# TN2115s1 register map
Vendor: Fusens Micro Ltd.; Series: TN21xx; File version: 1.0
ARM 32-bit Cortex-M0 Microcontroller Embedded in TN2115s1 device.
CPU: CM0 r0p0, little endian, no MPU, no FPU, 2 interrupt priority bits
Registers are 8-bit, read-write, reset 0x0 unless marked. A register's access mark holds for its fields unless they carry their own. Offsets are from the block's base; lines under a group give offsets from that group; [hi:lo] are bit positions; {n}, {i} and the like mark numbered series; 'fields as' and 'values as' point back to an identical list; <NAME> marks a mode.

## Memory map
0x40000000 I2C size 0x1C — I2C interface
0x40000100 SPI size 0x20 — SPI interface
0x40000200 UART size 0x18 — UART interface
0x40000300 NFC size 0x29 — NFC System Control
0x40000400 WDT size 0x10 — Watchdog Timer
0x40000404 TIM32 size 0x10 — General Purpose 32bit Timer
0x40000500 GPIO size 0xD
0x40000600 FLASH size 0x8

## Interrupts
0 UART
1 SPI
2 I2C
3 NFCTX (NFC)
4 NFCRX (NFC)
5 NFCFIELD (NFC)
6 TIM32
8 CAP_OK (NFC)

## WDT — Watchdog Timer
Base 0x40000400
0x00 CSR 32-bit reset 0x4 — Watchdog Control and Status Register

## I2C — I2C interface
Base 0x40000000
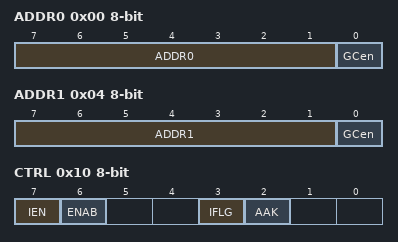
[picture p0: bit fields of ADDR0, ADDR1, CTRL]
0x00 ADDR0 — I2C Slave Address 0 Register
  [7:1] ADDR0 — Address 0
  [0] GCen — General call enable
    1=ON (General call enabled); 0=OFF (General call disabled)
0x04 ADDR1 — I2C Slave Address 1 Register
  [7:1] ADDR1 — Address 0
  [0] GCen — General call enable
    1=ON (General call enabled); 0=OFF (General call disabled)
0x0C DATA — I2C RTX Data Register
  [7:0] DATA — Data to receive or transmit
0x10 CTRL — I2C CTRL Register
  [7] IEN — Interrupt enable
    1=ON (Enabled); 0=OFF (Disabled)
  [6] ENAB — I2C Enable
    1=ON (Enabled); 0=OFF (Disabled)
  [3] IFLG — Interrupt flag
    1=SET (Interrupt set); 0=CLR (Interrupt clear)
  [2] AAK — Acknowlegement control
    1=ACK (Enable ACK); 0=NACK (Enable NACK)
0x18 STATUS — I2C Status Register
  [7:0] STAT ro — Status display
    0=ERR (Bus Error); 8=M_ST_TX (Start Txed); 16=M_ReST_TX (Restart Txed); 24=M_ADRWTX_ACK (Address+W TXed and ACKed); 32=M_ADRWTX (Address+W TXed); 40=M_TX_ACK (Data Txed and ACKed); 48=M_TX (Data Txed); 64=M_ADRRTX_ACK (Address+R TXed and ACKed); 72=M_ADRRTX (Address+R TXed); 80=M_RX_ACK (Data RXed and ACKed); 88=M_RX_NACK (Data RXed and NACKed); 96=S_ADRW_ACK (Address+W RXed and ACKed); 112=S_GC_ACK (General call RXed and ACKed); 128=S_RX_ACK (Data RXed and ACKed); 136=S_RX_NACK (Data RXed and NACKed); 160=S_ReST (Stop or Restart RXed); 168=S_ADRR_ACK (Address+R RXed and ACKed); 184=S_TX_ACK (Data TXed and ACKed); 192=S_TX (Data TXed); 200=S_TX_NACK (Data TXed and NACKed)
0x1C RESET — I2C Reset Register
  [7:0] SRST — Write any value to reset

## SPI — SPI interface
Base 0x40000100
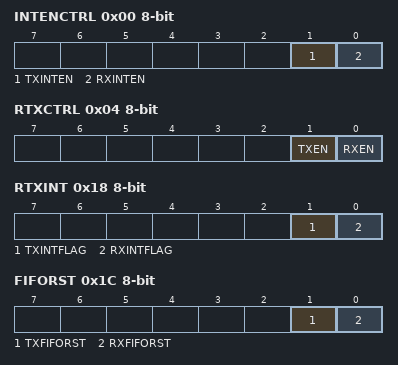
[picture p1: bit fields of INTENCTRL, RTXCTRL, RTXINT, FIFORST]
0x00 INTENCTRL — SPI Interrupt Control Register
  [1] TXINTEN — SPI TX underflow interrupt control
    1=ON (Enabled); 0=OFF (Disabled)
  [0] RXINTEN — SPI RX overflow interrupt control
    1=ON (Enabled); 0=OFF (Disabled)
0x04 RTXCTRL — SPI RTX Control Register
  [1] TXEN — SPI TX control
    1=ON (Enabled); 0=OFF (Disabled)
  [0] RXEN — SPI RX control
    1=ON (Enabled); 0=OFF (Disabled)
0x08 TXFIFO — SPI TX FIFO Register
0x0C RXFIFO — SPI TX FIFO Register
0x10 TXFIFOWMCTRL — SPI TX FIFO Watermark Control Register
  [2:0] TXFIFOWM — SPI TX FIFO underflow watermark control
0x14 RXFIFOWMCTRL — SPI RX FIFO Watermark Control Register
  [2:0] RXFIFOWM — SPI RX FIFO overflow watermark control
0x18 RTXINT — SPI RTX INT Flags Register
  [1] TXINTFLAG — SPI TX interrupt flag
    1=ON (Interrupt pending); 0=OFF (No interrupt)
  [0] RXINTFLAG — SPI RX interrupt flag
    1=ON (Interrupt pending); 0=OFF (No interrupt)
0x1C FIFORST — SPI RTX FIFO Reset Register
  [1] TXFIFORST — SPI TX FIFO reset
    1=ON (Reset); 0=OFF (Do not reset)
  [0] RXFIFORST — SPI RX FIFO reset
    1=ON (Reset); 0=OFF (Do not reset)

## Licence text in the file
ARM Limited (ARM) is supplying this software for use with Cortex-M processor based microcontroller, but can be equally used for other suitable processor architectures. This file can be freely distributed. Modifications to this file shall be clearly marked. . THIS SOFTWARE IS PROVIDED "AS IS". NO WARRANTIES, WHETHER EXPRESS, IMPLIED. OR STATUTORY, INCLUDING, BUT NOT LIMITED TO, IMPLIED WARRANTIES OF. MERCHANTABILITY AND FITNESS FOR A PARTICULAR PURPOSE APPLY TO THIS SOFTWARE. ARM SHALL NOT, IN ANY CIRCUMSTANCES, BE LIABLE FOR SPECIAL, INCIDENTAL, OR. CONSEQUENTIAL DAMAGES, FOR ANY REASON WHATSOEVER.

## Notices in the file
Copyright (C) 2012 ARM Limited. All rights reserved.
Purpose: System Viewer Description (SVD) Example (Schema Version 1.1)
This is a description of a none-existent and incomplete device
for demonstration purposes only.
Redistribution and use in source and binary forms, with or without
modification, are permitted provided that the following conditions are met:
- Redistributions of source code must retain the above copyright
notice, this list of conditions and the following disclaimer.
- Redistributions in binary form must reproduce the above copyright
notice, this list of conditions and the following disclaimer in the
documentation and/or other materials provided with the distribution.
- Neither the name of ARM nor the names of its contributors may be used
to endorse or promote products derived from this software without
specific prior written permission.
THIS SOFTWARE IS PROVIDED BY THE COPYRIGHT HOLDERS AND CONTRIBUTORS "AS IS"
AND ANY EXPRESS OR IMPLIED WARRANTIES, INCLUDING, BUT NOT LIMITED TO, THE
ARE DISCLAIMED. IN NO EVENT SHALL COPYRIGHT HOLDERS AND CONTRIBUTORS BE
LIABLE FOR ANY DIRECT, INDIRECT, INCIDENTAL, SPECIAL, EXEMPLARY, OR
CONSEQUENTIAL DAMAGES (INCLUDING, BUT NOT LIMITED TO, PROCUREMENT OF
SUBSTITUTE GOODS OR SERVICES; LOSS OF USE, DATA, OR PROFITS; OR BUSINESS
INTERRUPTION) HOWEVER CAUSED AND ON ANY THEORY OF LIABILITY, WHETHER IN
CONTRACT, STRICT LIABILITY, OR TORT (INCLUDING NEGLIGENCE OR OTHERWISE)
ARISING IN ANY WAY OUT OF THE USE OF THIS SOFTWARE, EVEN IF ADVISED OF THE
POSSIBILITY OF SUCH DAMAGE.
